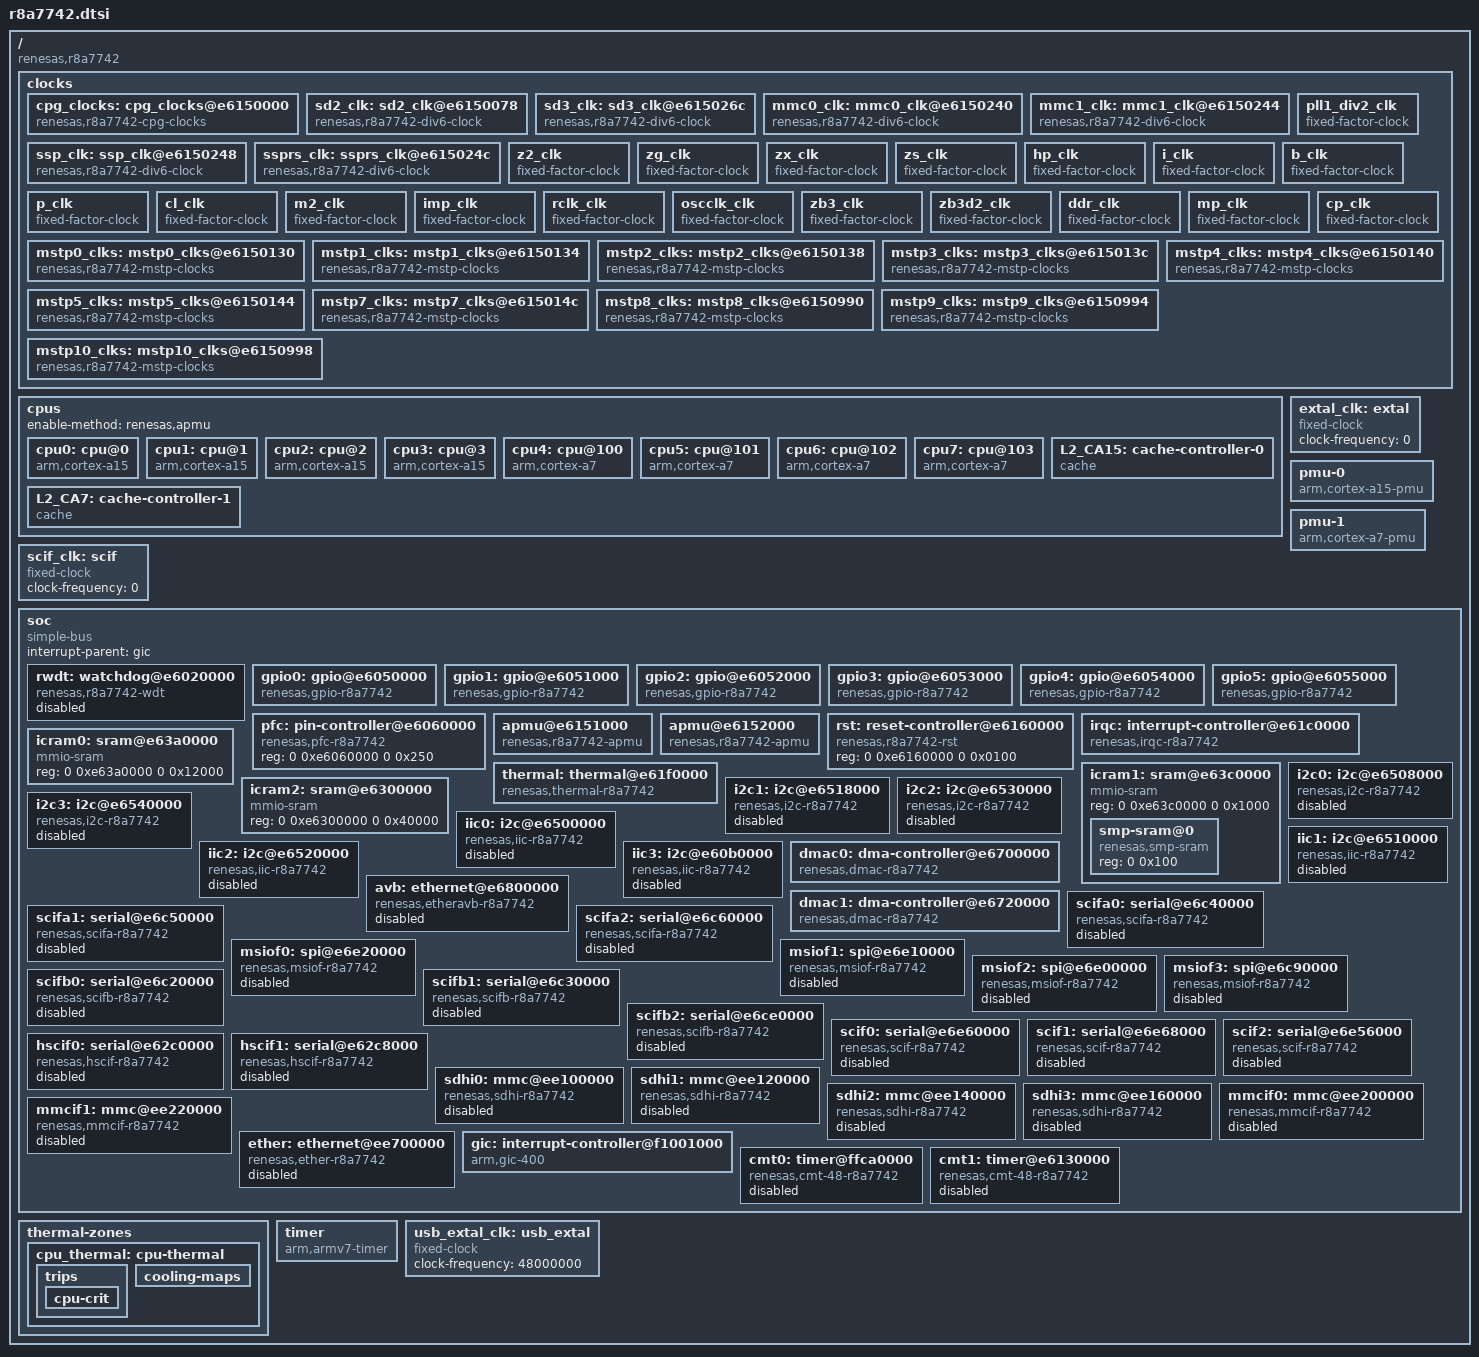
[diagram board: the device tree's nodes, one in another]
// SPDX-License-Identifier: GPL-2.0
/*
 * Device Tree Source for the r8a7742 SoC
 *
 * Copyright (C) 2020 Renesas Electronics Corp.
 */

#include <dt-bindings/interrupt-controller/arm-gic.h>
#include <dt-bindings/interrupt-controller/irq.h>
#include <dt-bindings/clock/r8a7742-clock.h>

/ {
	compatible = "renesas,r8a7742";
	#address-cells = <2>;
	#size-cells = <2>;

	clocks {
		#address-cells = <2>;
		#size-cells = <2>;
		ranges;

		/* Special CPG clocks */
		cpg_clocks: cpg_clocks@e6150000 {
			compatible = "renesas,r8a7742-cpg-clocks",
				     "renesas,rcar-gen2-cpg-clocks";
			reg = <0 0xe6150000 0 0x1000>;
			clocks = <&extal_clk &usb_extal_clk>;
			#clock-cells = <1>;
			clock-output-names = "main", "pll0", "pll1", "pll3",
					     "lb", "qspi", "sdh", "sd0", "sd1",
					     "z", "rcan";
			#power-domain-cells = <0>;
		};

		/* Variable factor clocks */
		sd2_clk: sd2_clk@e6150078 {
			compatible = "renesas,r8a7742-div6-clock", "renesas,cpg-div6-clock";
			reg = <0 0xe6150078 0 4>;
			clocks = <&pll1_div2_clk>;
			#clock-cells = <0>;
			clock-output-names = "sd2";
		};
		sd3_clk: sd3_clk@e615026c {
			compatible = "renesas,r8a7742-div6-clock", "renesas,cpg-div6-clock";
			reg = <0 0xe615026c 0 4>;
			clocks = <&pll1_div2_clk>;
			#clock-cells = <0>;
			clock-output-names = "sd3";
		};
		mmc0_clk: mmc0_clk@e6150240 {
			compatible = "renesas,r8a7742-div6-clock", "renesas,cpg-div6-clock";
			reg = <0 0xe6150240 0 4>;
			clocks = <&pll1_div2_clk>;
			#clock-cells = <0>;
			clock-output-names = "mmc0";
		};
		mmc1_clk: mmc1_clk@e6150244 {
			compatible = "renesas,r8a7742-div6-clock", "renesas,cpg-div6-clock";
			reg = <0 0xe6150244 0 4>;
			clocks = <&pll1_div2_clk>;
			#clock-cells = <0>;
			clock-output-names = "mmc1";
		};
		ssp_clk: ssp_clk@e6150248 {
			compatible = "renesas,r8a7742-div6-clock", "renesas,cpg-div6-clock";
			reg = <0 0xe6150248 0 4>;
			clocks = <&pll1_div2_clk>;
			#clock-cells = <0>;
			clock-output-names = "ssp";
		};
		ssprs_clk: ssprs_clk@e615024c {
			compatible = "renesas,r8a7742-div6-clock", "renesas,cpg-div6-clock";
			reg = <0 0xe615024c 0 4>;
			clocks = <&pll1_div2_clk>;
			#clock-cells = <0>;
			clock-output-names = "ssprs";
		};

		/* Fixed factor clocks */
		pll1_div2_clk: pll1_div2_clk {
			compatible = "fixed-factor-clock";
			clocks = <&cpg_clocks R8A7742_CLK_PLL1>;
			#clock-cells = <0>;
			clock-div = <2>;
			clock-mult = <1>;
			clock-output-names = "pll1_div2";
		};
		z2_clk: z2_clk {
			compatible = "fixed-factor-clock";
			clocks = <&cpg_clocks R8A7742_CLK_PLL1>;
			#clock-cells = <0>;
			clock-div = <2>;
			clock-mult = <1>;
			clock-output-names = "z2";
		};
		zg_clk: zg_clk {
			compatible = "fixed-factor-clock";
			clocks = <&cpg_clocks R8A7742_CLK_PLL1>;
			#clock-cells = <0>;
			clock-div = <3>;
			clock-mult = <1>;
			clock-output-names = "zg";
		};
		zx_clk: zx_clk {
			compatible = "fixed-factor-clock";
			clocks = <&cpg_clocks R8A7742_CLK_PLL1>;
			#clock-cells = <0>;
			clock-div = <3>;
			clock-mult = <1>;
			clock-output-names = "zx";
		};
		zs_clk: zs_clk {
			compatible = "fixed-factor-clock";
			clocks = <&cpg_clocks R8A7742_CLK_PLL1>;
			#clock-cells = <0>;
			clock-div = <6>;
			clock-mult = <1>;
			clock-output-names = "zs";
		};
		hp_clk: hp_clk {
			compatible = "fixed-factor-clock";
			clocks = <&cpg_clocks R8A7742_CLK_PLL1>;
			#clock-cells = <0>;
			clock-div = <12>;
			clock-mult = <1>;
			clock-output-names = "hp";
		};
		i_clk: i_clk {
			compatible = "fixed-factor-clock";
			clocks = <&cpg_clocks R8A7742_CLK_PLL1>;
			#clock-cells = <0>;
			clock-div = <2>;
			clock-mult = <1>;
			clock-output-names = "i";
		};
		b_clk: b_clk {
			compatible = "fixed-factor-clock";
			clocks = <&cpg_clocks R8A7742_CLK_PLL1>;
			#clock-cells = <0>;
			clock-div = <12>;
			clock-mult = <1>;
			clock-output-names = "b";
		};
		p_clk: p_clk {
			compatible = "fixed-factor-clock";
			clocks = <&cpg_clocks R8A7742_CLK_PLL1>;
			#clock-cells = <0>;
			clock-div = <24>;
			clock-mult = <1>;
			clock-output-names = "p";
		};
		cl_clk: cl_clk {
			compatible = "fixed-factor-clock";
			clocks = <&cpg_clocks R8A7742_CLK_PLL1>;
			#clock-cells = <0>;
			clock-div = <48>;
			clock-mult = <1>;
			clock-output-names = "cl";
		};
		m2_clk: m2_clk {
			compatible = "fixed-factor-clock";
			clocks = <&cpg_clocks R8A7742_CLK_PLL1>;
			#clock-cells = <0>;
			clock-div = <8>;
			clock-mult = <1>;
			clock-output-names = "m2";
		};
		imp_clk: imp_clk {
			compatible = "fixed-factor-clock";
			clocks = <&cpg_clocks R8A7742_CLK_PLL1>;
			#clock-cells = <0>;
			clock-div = <4>;
			clock-mult = <1>;
			clock-output-names = "imp";
		};
		rclk_clk: rclk_clk {
			compatible = "fixed-factor-clock";
			clocks = <&cpg_clocks R8A7742_CLK_PLL1>;
			#clock-cells = <0>;
			clock-div = <(48 * 1024)>;
			clock-mult = <1>;
			clock-output-names = "rclk";
		};
		oscclk_clk: oscclk_clk {
			compatible = "fixed-factor-clock";
			clocks = <&cpg_clocks R8A7742_CLK_PLL1>;
			#clock-cells = <0>;
			clock-div = <(12 * 1024)>;
			clock-mult = <1>;
			clock-output-names = "oscclk";
		};
		zb3_clk: zb3_clk {
			compatible = "fixed-factor-clock";
			clocks = <&cpg_clocks R8A7742_CLK_PLL3>;
			#clock-cells = <0>;
			clock-div = <4>;
			clock-mult = <1>;
			clock-output-names = "zb3";
		};
		zb3d2_clk: zb3d2_clk {
			compatible = "fixed-factor-clock";
			clocks = <&cpg_clocks R8A7742_CLK_PLL3>;
			#clock-cells = <0>;
			clock-div = <8>;
			clock-mult = <1>;
			clock-output-names = "zb3d2";
		};
		ddr_clk: ddr_clk {
			compatible = "fixed-factor-clock";
			clocks = <&cpg_clocks R8A7742_CLK_PLL3>;
			#clock-cells = <0>;
			clock-div = <8>;
			clock-mult = <1>;
			clock-output-names = "ddr";
		};
		mp_clk: mp_clk {
			compatible = "fixed-factor-clock";
			clocks = <&pll1_div2_clk>;
			#clock-cells = <0>;
			clock-div = <15>;
			clock-mult = <1>;
			clock-output-names = "mp";
		};
		cp_clk: cp_clk {
			compatible = "fixed-factor-clock";
			clocks = <&extal_clk>;
			#clock-cells = <0>;
			clock-div = <2>;
			clock-mult = <1>;
			clock-output-names = "cp";
		};

		/* Gate clocks */
		mstp0_clks: mstp0_clks@e6150130 {
			compatible = "renesas,r8a7742-mstp-clocks", "renesas,cpg-mstp-clocks";
			reg = <0 0xe6150130 0 4>, <0 0xe6150030 0 4>;
			clocks = <&mp_clk>;
			#clock-cells = <1>;
			clock-indices = <R8A7742_CLK_MSIOF0>;
			clock-output-names = "msiof0";
		};
		mstp1_clks: mstp1_clks@e6150134 {
			compatible = "renesas,r8a7742-mstp-clocks", "renesas,cpg-mstp-clocks";
			reg = <0 0xe6150134 0 4>, <0 0xe6150038 0 4>;
			clocks = <&zs_clk>, <&zs_clk>, <&zs_clk>, <&zs_clk>,
				 <&p_clk>, <&zg_clk>, <&zs_clk>, <&zs_clk>,
				 <&zs_clk>, <&zs_clk>, <&p_clk>, <&p_clk>,
				 <&rclk_clk>, <&cp_clk>, <&zs_clk>, <&zs_clk>,
				 <&zs_clk>, <&zs_clk>;
			#clock-cells = <1>;
			clock-indices = <
				R8A7742_CLK_VCP1 R8A7742_CLK_VCP0
				R8A7742_CLK_VPC1 R8A7742_CLK_VPC0
				R8A7742_CLK_TMU1 R8A7742_CLK_3DG
				R8A7742_CLK_2DDMAC R8A7742_CLK_FDP1_2
				R8A7742_CLK_FDP1_1 R8A7742_CLK_FDP1_0
				R8A7742_CLK_TMU3 R8A7742_CLK_TMU2
				R8A7742_CLK_CMT0 R8A7742_CLK_TMU0
				R8A7742_CLK_VSP1_DU1 R8A7742_CLK_VSP1_DU0
				R8A7742_CLK_VSP1_R R8A7742_CLK_VSP1_S
			>;
			clock-output-names =
				"vcp1", "vcp0", "vpc1", "vpc0", "tmu1",
				"3dg", "2ddmac", "fdp1-2", "fdp1-1", "fdp1-0",
				"tmu3", "tmu2", "cmt0", "tmu0", "vsp1-du1",
				"vsp1-du0", "vspr", "vsps";
		};
		mstp2_clks: mstp2_clks@e6150138 {
			compatible = "renesas,r8a7742-mstp-clocks", "renesas,cpg-mstp-clocks";
			reg = <0 0xe6150138 0 4>, <0 0xe6150040 0 4>;
			clocks = <&mp_clk>, <&mp_clk>, <&mp_clk>, <&mp_clk>, <&mp_clk>,
				 <&mp_clk>, <&mp_clk>, <&mp_clk>, <&mp_clk>, <&zs_clk>,
				 <&zs_clk>;
			#clock-cells = <1>;
			clock-indices = <
				R8A7742_CLK_SCIFA2 R8A7742_CLK_SCIFA1 R8A7742_CLK_SCIFA0
				R8A7742_CLK_MSIOF2 R8A7742_CLK_SCIFB0 R8A7742_CLK_SCIFB1
				R8A7742_CLK_MSIOF1 R8A7742_CLK_MSIOF3 R8A7742_CLK_SCIFB2
				R8A7742_CLK_SYS_DMAC1 R8A7742_CLK_SYS_DMAC0
			>;
			clock-output-names =
				"scifa2", "scifa1", "scifa0", "msiof2", "scifb0",
				"scifb1", "msiof1", "msiof3", "scifb2",
				"sys-dmac1", "sys-dmac0";
		};
		mstp3_clks: mstp3_clks@e615013c {
			compatible = "renesas,r8a7742-mstp-clocks", "renesas,cpg-mstp-clocks";
			reg = <0 0xe615013c 0 4>, <0 0xe6150048 0 4>;
			clocks = <&hp_clk>, <&cp_clk>, <&mmc1_clk>, <&p_clk>, <&sd3_clk>,
				 <&sd2_clk>, <&cpg_clocks R8A7742_CLK_SD1>, <&cpg_clocks R8A7742_CLK_SD0>, <&mmc0_clk>,
				 <&hp_clk>, <&mp_clk>, <&hp_clk>, <&mp_clk>, <&rclk_clk>,
				 <&hp_clk>, <&hp_clk>;
			#clock-cells = <1>;
			clock-indices = <
				R8A7742_CLK_IIC2 R8A7742_CLK_TPU0 R8A7742_CLK_MMCIF1 R8A7742_CLK_SCIF2 R8A7742_CLK_SDHI3
				R8A7742_CLK_SDHI2 R8A7742_CLK_SDHI1 R8A7742_CLK_SDHI0 R8A7742_CLK_MMCIF0
				R8A7742_CLK_IIC0 R8A7742_CLK_PCIEC R8A7742_CLK_IIC1 R8A7742_CLK_SSUSB R8A7742_CLK_CMT1
				R8A7742_CLK_USBDMAC0 R8A7742_CLK_USBDMAC1
			>;
			clock-output-names =
				"iic2", "tpu0", "mmcif1", "scif2", "sdhi3",
				"sdhi2", "sdhi1", "sdhi0", "mmcif0",
				"iic0", "pciec", "iic1", "ssusb", "cmt1",
				"usbdmac0", "usbdmac1";
		};
		mstp4_clks: mstp4_clks@e6150140 {
			compatible = "renesas,r8a7742-mstp-clocks", "renesas,cpg-mstp-clocks";
			reg = <0 0xe6150140 0 4>, <0 0xe615004c 0 4>;
			clocks = <&cp_clk>, <&rclk_clk>, <&zs_clk>;
			#clock-cells = <1>;
			clock-indices = <R8A7742_CLK_IRQC R8A7742_CLK_RWDT R8A7742_CLK_INTC_SYS>;
			clock-output-names = "irqc", "rwdt", "intc-sys";
		};
		mstp5_clks: mstp5_clks@e6150144 {
			compatible = "renesas,r8a7742-mstp-clocks", "renesas,cpg-mstp-clocks";
			reg = <0 0xe6150144 0 4>, <0 0xe615003c 0 4>;
			clocks = <&hp_clk>, <&hp_clk>,
				 <&extal_clk>, <&p_clk>;
			#clock-cells = <1>;
			clock-indices = <
				R8A7742_CLK_AUDIO_DMAC0 R8A7742_CLK_AUDIO_DMAC1
				R8A7742_CLK_THERMAL R8A7742_CLK_PWM
			>;
			clock-output-names = "audmac0", "audmac1",
					     "thermal", "pwm";
		};
		mstp7_clks: mstp7_clks@e615014c {
			compatible = "renesas,r8a7742-mstp-clocks", "renesas,cpg-mstp-clocks";
			reg = <0 0xe615014c 0 4>, <0 0xe61501c4 0 4>;
			clocks = <&mp_clk>, <&hp_clk>, <&zs_clk>, <&zs_clk>, <&p_clk>,
				 <&p_clk>, <&zx_clk>, <&zx_clk>, <&zx_clk>, <&zx_clk>,
				 <&zx_clk>;
			#clock-cells = <1>;
			clock-indices = <
				R8A7742_CLK_EHCI R8A7742_CLK_HSUSB R8A7742_CLK_HSCIF1
				R8A7742_CLK_HSCIF0 R8A7742_CLK_SCIF1 R8A7742_CLK_SCIF0
				R8A7742_CLK_DU2 R8A7742_CLK_DU1 R8A7742_CLK_DU0
				R8A7742_CLK_LVDS1 R8A7742_CLK_LVDS0
			>;
			clock-output-names =
				"ehci", "hsusb", "hscif1", "hscif0", "scif1",
				"scif0", "du2", "du1", "du0", "lvds1", "lvds0";
		};
		mstp8_clks: mstp8_clks@e6150990 {
			compatible = "renesas,r8a7742-mstp-clocks", "renesas,cpg-mstp-clocks";
			reg = <0 0xe6150990 0 4>, <0 0xe61509a0 0 4>;
			clocks = <&zx_clk>, <&zg_clk>, <&zg_clk>, <&zg_clk>,
				 <&zg_clk>, <&hp_clk>, <&p_clk>, <&zs_clk>,
				 <&zs_clk>, <&zg_clk>, <&hp_clk>, <&p_clk>, <&zs_clk>;
			#clock-cells = <1>;
			clock-indices = <
				R8A7742_CLK_R_GP2D R8A7742_CLK_VIN3 R8A7742_CLK_VIN2
				R8A7742_CLK_VIN1 R8A7742_CLK_VIN0
				R8A7742_CLK_ETHERAVB R8A7742_CLK_ETHER
				R8A7742_CLK_SATA1 R8A7742_CLK_SATA0
				R8A7742_CLK_IMR_X2_1 R8A7742_CLK_IMR_X2_0
				R8A7742_CLK_IMR_LSX2_1 R8A7742_CLK_IMR_LSX2_0
			>;
			clock-output-names =
				"r-gp2d", "vin3", "vin2", "vin1", "vin0",
				"etheravb", "ether", "sata1", "sata0",
				"imr-x2-1", "imr-x2-0", "imr-lsx2-1", "imr-lsx2-0";
		};
		mstp9_clks: mstp9_clks@e6150994 {
			compatible = "renesas,r8a7742-mstp-clocks", "renesas,cpg-mstp-clocks";
			reg = <0 0xe6150994 0 4>, <0 0xe61509a4 0 4>;
			clocks = <&cp_clk>, <&cp_clk>, <&cp_clk>,
				 <&cp_clk>, <&cp_clk>, <&cp_clk>,
				 <&p_clk>, <&p_clk>, <&cpg_clocks R8A7742_CLK_QSPI>, <&cp_clk>,
				 <&hp_clk>, <&hp_clk>, <&hp_clk>, <&hp_clk>;
			#clock-cells = <1>;
			clock-indices = <
				R8A7742_CLK_GPIO5 R8A7742_CLK_GPIO4 R8A7742_CLK_GPIO3
				R8A7742_CLK_GPIO2 R8A7742_CLK_GPIO1 R8A7742_CLK_GPIO0
				R8A7742_CLK_RCAN1 R8A7742_CLK_RCAN0 R8A7742_CLK_QSPI_MOD R8A7742_CLK_IICDVFS
				R8A7742_CLK_I2C3 R8A7742_CLK_I2C2 R8A7742_CLK_I2C1 R8A7742_CLK_I2C0
			>;
			clock-output-names =
				"gpio5", "gpio4", "gpio3", "gpio2", "gpio1", "gpio0",
				"rcan1", "rcan0", "qspi_mod", "iic3",
				"i2c3", "i2c2", "i2c1", "i2c0";
		};
		mstp10_clks: mstp10_clks@e6150998 {
			compatible = "renesas,r8a7742-mstp-clocks", "renesas,cpg-mstp-clocks";
			reg = <0 0xe6150998 0 4>, <0 0xe61509a8 0 4>;
			clocks = <&p_clk>,
				<&mstp10_clks R8A7742_CLK_SSI_ALL>, <&mstp10_clks R8A7742_CLK_SSI_ALL>,
				<&mstp10_clks R8A7742_CLK_SSI_ALL>, <&mstp10_clks R8A7742_CLK_SSI_ALL>,
				<&mstp10_clks R8A7742_CLK_SSI_ALL>, <&mstp10_clks R8A7742_CLK_SSI_ALL>,
				<&mstp10_clks R8A7742_CLK_SSI_ALL>, <&mstp10_clks R8A7742_CLK_SSI_ALL>,
				<&mstp10_clks R8A7742_CLK_SSI_ALL>, <&mstp10_clks R8A7742_CLK_SSI_ALL>,
				<&p_clk>,
				<&mstp10_clks R8A7742_CLK_SCU_ALL>, <&mstp10_clks R8A7742_CLK_SCU_ALL>,
				<&mstp10_clks R8A7742_CLK_SCU_ALL>, <&mstp10_clks R8A7742_CLK_SCU_ALL>,
				<&mstp10_clks R8A7742_CLK_SCU_ALL>, <&mstp10_clks R8A7742_CLK_SCU_ALL>,
				<&mstp10_clks R8A7742_CLK_SCU_ALL>, <&mstp10_clks R8A7742_CLK_SCU_ALL>,
				<&mstp10_clks R8A7742_CLK_SCU_ALL>, <&mstp10_clks R8A7742_CLK_SCU_ALL>,
				<&mstp10_clks R8A7742_CLK_SCU_ALL>, <&mstp10_clks R8A7742_CLK_SCU_ALL>,
				<&mstp10_clks R8A7742_CLK_SCU_ALL>, <&mstp10_clks R8A7742_CLK_SCU_ALL>;

			#clock-cells = <1>;
			clock-indices = <
				R8A7742_CLK_SSI_ALL
				R8A7742_CLK_SSI9 R8A7742_CLK_SSI8 R8A7742_CLK_SSI7 R8A7742_CLK_SSI6 R8A7742_CLK_SSI5
				R8A7742_CLK_SSI4 R8A7742_CLK_SSI3 R8A7742_CLK_SSI2 R8A7742_CLK_SSI1 R8A7742_CLK_SSI0
				R8A7742_CLK_SCU_ALL
				R8A7742_CLK_SCU_DVC1 R8A7742_CLK_SCU_DVC0
				R8A7742_CLK_SCU_CTU1_MIX1 R8A7742_CLK_SCU_CTU0_MIX0
				R8A7742_CLK_SCU_SRC9 R8A7742_CLK_SCU_SRC8 R8A7742_CLK_SCU_SRC7 R8A7742_CLK_SCU_SRC6 R8A7742_CLK_SCU_SRC5
				R8A7742_CLK_SCU_SRC4 R8A7742_CLK_SCU_SRC3 R8A7742_CLK_SCU_SRC2 R8A7742_CLK_SCU_SRC1 R8A7742_CLK_SCU_SRC0
			>;
			clock-output-names =
				"ssi-all",
				"ssi9", "ssi8", "ssi7", "ssi6", "ssi5",
				"ssi4", "ssi3", "ssi2", "ssi1", "ssi0",
				"scu-all",
				"scu-dvc1", "scu-dvc0",
				"scu-ctu1-mix1", "scu-ctu0-mix0",
				"scu-src9", "scu-src8", "scu-src7", "scu-src6", "scu-src5",
				"scu-src4", "scu-src3", "scu-src2", "scu-src1", "scu-src0";
		};
	};

	cpus {
		#address-cells = <1>;
		#size-cells = <0>;
		enable-method = "renesas,apmu";

		cpu0: cpu@0 {
			device_type = "cpu";
			compatible = "arm,cortex-a15";
			reg = <0>;
			clock-frequency = <1400000000>;
			clocks = <&cpg_clocks R8A7742_CLK_Z>;
			power-domains = <&cpg_clocks>;
			next-level-cache = <&L2_CA15>;
			capacity-dmips-mhz = <1024>;
			voltage-tolerance = <1>; /* 1% */
			clock-latency = <300000>; /* 300 us */

			/* kHz - uV - OPPs unknown yet */
			operating-points = <1400000 1000000>,
					   <1225000 1000000>,
					   <1050000 1000000>,
					   < 875000 1000000>,
					   < 700000 1000000>,
					   < 350000 1000000>;
		};

		cpu1: cpu@1 {
			device_type = "cpu";
			compatible = "arm,cortex-a15";
			reg = <1>;
			clock-frequency = <1400000000>;
			clocks = <&cpg_clocks R8A7742_CLK_Z>;
			power-domains = <&cpg_clocks>;
			next-level-cache = <&L2_CA15>;
			capacity-dmips-mhz = <1024>;
			voltage-tolerance = <1>; /* 1% */
			clock-latency = <300000>; /* 300 us */

			/* kHz - uV - OPPs unknown yet */
			operating-points = <1400000 1000000>,
					   <1225000 1000000>,
					   <1050000 1000000>,
					   < 875000 1000000>,
					   < 700000 1000000>,
					   < 350000 1000000>;
		};

		cpu2: cpu@2 {
			device_type = "cpu";
			compatible = "arm,cortex-a15";
			reg = <2>;
			clock-frequency = <1400000000>;
			clocks = <&cpg_clocks R8A7742_CLK_Z>;
			power-domains = <&cpg_clocks>;
			next-level-cache = <&L2_CA15>;
			capacity-dmips-mhz = <1024>;
			voltage-tolerance = <1>; /* 1% */
			clock-latency = <300000>; /* 300 us */

			/* kHz - uV - OPPs unknown yet */
			operating-points = <1400000 1000000>,
					   <1225000 1000000>,
					   <1050000 1000000>,
					   < 875000 1000000>,
					   < 700000 1000000>,
					   < 350000 1000000>;
		};

		cpu3: cpu@3 {
			device_type = "cpu";
			compatible = "arm,cortex-a15";
			reg = <3>;
			clock-frequency = <1400000000>;
			clocks = <&cpg_clocks R8A7742_CLK_Z>;
			power-domains = <&cpg_clocks>;
			next-level-cache = <&L2_CA15>;
			capacity-dmips-mhz = <1024>;
			voltage-tolerance = <1>; /* 1% */
			clock-latency = <300000>; /* 300 us */

			/* kHz - uV - OPPs unknown yet */
			operating-points = <1400000 1000000>,
					   <1225000 1000000>,
					   <1050000 1000000>,
					   < 875000 1000000>,
					   < 700000 1000000>,
					   < 350000 1000000>;
		};

		cpu4: cpu@100 {
			device_type = "cpu";
			compatible = "arm,cortex-a7";
			reg = <0x100>;
			clock-frequency = <780000000>;
			clocks = <&cpg_clocks R8A7742_CLK_Z2>;
			power-domains = <&cpg_clocks>;
			next-level-cache = <&L2_CA7>;
		};

		cpu5: cpu@101 {
			device_type = "cpu";
			compatible = "arm,cortex-a7";
			reg = <0x101>;
			clock-frequency = <780000000>;
			clocks = <&cpg_clocks R8A7742_CLK_Z2>;
			power-domains = <&cpg_clocks>;
			next-level-cache = <&L2_CA7>;
		};

		cpu6: cpu@102 {
			device_type = "cpu";
			compatible = "arm,cortex-a7";
			reg = <0x102>;
			clock-frequency = <780000000>;
			clocks = <&cpg_clocks R8A7742_CLK_Z2>;
			power-domains = <&cpg_clocks>;
			next-level-cache = <&L2_CA7>;
		};

		cpu7: cpu@103 {
			device_type = "cpu";
			compatible = "arm,cortex-a7";
			reg = <0x103>;
			clock-frequency = <780000000>;
			clocks = <&cpg_clocks R8A7742_CLK_Z2>;
			power-domains = <&cpg_clocks>;
			next-level-cache = <&L2_CA7>;
		};

		L2_CA15: cache-controller-0 {
			compatible = "cache";
			power-domains = <&cpg_clocks>;
			cache-unified;
			cache-level = <2>;
		};

		L2_CA7: cache-controller-1 {
			compatible = "cache";
			power-domains = <&cpg_clocks>;
			cache-unified;
			cache-level = <2>;
		};
	};

	/* External root clock */
	extal_clk: extal {
		compatible = "fixed-clock";
		#clock-cells = <0>;
		/* This value must be overridden by the board. */
		clock-frequency = <0>;
	};

	pmu-0 {
		compatible = "arm,cortex-a15-pmu";
		interrupts-extended = <&gic GIC_SPI 72 IRQ_TYPE_LEVEL_HIGH>,
				      <&gic GIC_SPI 73 IRQ_TYPE_LEVEL_HIGH>,
				      <&gic GIC_SPI 74 IRQ_TYPE_LEVEL_HIGH>,
				      <&gic GIC_SPI 75 IRQ_TYPE_LEVEL_HIGH>;
		interrupt-affinity = <&cpu0>, <&cpu1>, <&cpu2>, <&cpu3>;
	};

	pmu-1 {
		compatible = "arm,cortex-a7-pmu";
		interrupts-extended = <&gic GIC_SPI 82 IRQ_TYPE_LEVEL_HIGH>,
				      <&gic GIC_SPI 83 IRQ_TYPE_LEVEL_HIGH>,
				      <&gic GIC_SPI 84 IRQ_TYPE_LEVEL_HIGH>,
				      <&gic GIC_SPI 85 IRQ_TYPE_LEVEL_HIGH>;
		interrupt-affinity = <&cpu4>, <&cpu5>, <&cpu6>, <&cpu7>;
	};

	/* External SCIF clock */
	scif_clk: scif {
		compatible = "fixed-clock";
		#clock-cells = <0>;
		/* This value must be overridden by the board. */
		clock-frequency = <0>;
	};

	soc {
		compatible = "simple-bus";
		interrupt-parent = <&gic>;

		#address-cells = <2>;
		#size-cells = <2>;
		ranges;

		rwdt: watchdog@e6020000 {
			compatible = "renesas,r8a7742-wdt",
				     "renesas,rcar-gen2-wdt";
			reg = <0 0xe6020000 0 0x0c>;
			interrupts = <GIC_SPI 140 IRQ_TYPE_LEVEL_HIGH>;
			clocks = <&mstp4_clks R8A7742_CLK_RWDT>;
			power-domains = <&cpg_clocks>;
			status = "disabled";
		};

		gpio0: gpio@e6050000 {
			compatible = "renesas,gpio-r8a7742",
				     "renesas,rcar-gen2-gpio";
			reg = <0 0xe6050000 0 0x50>;
			interrupts = <GIC_SPI 4 IRQ_TYPE_LEVEL_HIGH>;
			#gpio-cells = <2>;
			gpio-controller;
			gpio-ranges = <&pfc 0 0 32>;
			#interrupt-cells = <2>;
			interrupt-controller;
			clocks = <&mstp9_clks R8A7742_CLK_GPIO0>;
			power-domains = <&cpg_clocks>;
		};

		gpio1: gpio@e6051000 {
			compatible = "renesas,gpio-r8a7742",
				     "renesas,rcar-gen2-gpio";
			reg = <0 0xe6051000 0 0x50>;
			interrupts = <GIC_SPI 5 IRQ_TYPE_LEVEL_HIGH>;
			#gpio-cells = <2>;
			gpio-controller;
			gpio-ranges = <&pfc 0 32 30>;
			#interrupt-cells = <2>;
			interrupt-controller;
			clocks = <&mstp9_clks R8A7742_CLK_GPIO1>;
			power-domains = <&cpg_clocks>;
		};

		gpio2: gpio@e6052000 {
			compatible = "renesas,gpio-r8a7742",
				     "renesas,rcar-gen2-gpio";
			reg = <0 0xe6052000 0 0x50>;
			interrupts = <GIC_SPI 6 IRQ_TYPE_LEVEL_HIGH>;
			#gpio-cells = <2>;
			gpio-controller;
			gpio-ranges = <&pfc 0 64 30>;
			#interrupt-cells = <2>;
			interrupt-controller;
			clocks = <&mstp9_clks R8A7742_CLK_GPIO2>;
			power-domains = <&cpg_clocks>;
		};

		gpio3: gpio@e6053000 {
			compatible = "renesas,gpio-r8a7742",
				     "renesas,rcar-gen2-gpio";
			reg = <0 0xe6053000 0 0x50>;
			interrupts = <GIC_SPI 7 IRQ_TYPE_LEVEL_HIGH>;
			#gpio-cells = <2>;
			gpio-controller;
			gpio-ranges = <&pfc 0 96 32>;
			#interrupt-cells = <2>;
			interrupt-controller;
			clocks = <&mstp9_clks R8A7742_CLK_GPIO3>;
			power-domains = <&cpg_clocks>;
		};

		gpio4: gpio@e6054000 {
			compatible = "renesas,gpio-r8a7742",
				     "renesas,rcar-gen2-gpio";
			reg = <0 0xe6054000 0 0x50>;
			interrupts = <GIC_SPI 8 IRQ_TYPE_LEVEL_HIGH>;
			#gpio-cells = <2>;
			gpio-controller;
			gpio-ranges = <&pfc 0 128 32>;
			#interrupt-cells = <2>;
			interrupt-controller;
			clocks = <&mstp9_clks R8A7742_CLK_GPIO4>;
			power-domains = <&cpg_clocks>;
		};

		gpio5: gpio@e6055000 {
			compatible = "renesas,gpio-r8a7742",
				     "renesas,rcar-gen2-gpio";
			reg = <0 0xe6055000 0 0x50>;
			interrupts = <GIC_SPI 9 IRQ_TYPE_LEVEL_HIGH>;
			#gpio-cells = <2>;
			gpio-controller;
			gpio-ranges = <&pfc 0 160 32>;
			#interrupt-cells = <2>;
			interrupt-controller;
			clocks = <&mstp9_clks R8A7742_CLK_GPIO5>;
			power-domains = <&cpg_clocks>;
		};

		pfc: pin-controller@e6060000 {
			compatible = "renesas,pfc-r8a7742";
			reg = <0 0xe6060000 0 0x250>;
		};

		apmu@e6151000 {
			compatible = "renesas,r8a7742-apmu", "renesas,apmu";
			reg = <0 0xe6151000 0 0x188>;
			cpus = <&cpu4 &cpu5 &cpu6 &cpu7>;
		};

		apmu@e6152000 {
			compatible = "renesas,r8a7742-apmu", "renesas,apmu";
			reg = <0 0xe6152000 0 0x188>;
			cpus = <&cpu0 &cpu1 &cpu2 &cpu3>;
		};

		rst: reset-controller@e6160000 {
			compatible = "renesas,r8a7742-rst";
			reg = <0 0xe6160000 0 0x0100>;
		};

		irqc: interrupt-controller@e61c0000 {
			compatible = "renesas,irqc-r8a7742", "renesas,irqc";
			#interrupt-cells = <2>;
			interrupt-controller;
			reg = <0 0xe61c0000 0 0x200>;
			interrupts = <GIC_SPI 0 IRQ_TYPE_LEVEL_HIGH>,
				     <GIC_SPI 1 IRQ_TYPE_LEVEL_HIGH>,
				     <GIC_SPI 2 IRQ_TYPE_LEVEL_HIGH>,
				     <GIC_SPI 3 IRQ_TYPE_LEVEL_HIGH>;
			clocks = <&mstp4_clks R8A7742_CLK_IRQC>;
			power-domains = <&cpg_clocks>;
		};

		thermal: thermal@e61f0000 {
			compatible = "renesas,thermal-r8a7742",
				     "renesas,rcar-gen2-thermal";
			reg = <0 0xe61f0000 0 0x10>, <0 0xe61f0100 0 0x38>;
			interrupts = <GIC_SPI 69 IRQ_TYPE_LEVEL_HIGH>;
			clocks = <&mstp5_clks R8A7742_CLK_THERMAL>;
			power-domains = <&cpg_clocks>;
			#thermal-sensor-cells = <0>;
		};

		icram0: sram@e63a0000 {
			compatible = "mmio-sram";
			reg = <0 0xe63a0000 0 0x12000>;
			#address-cells = <1>;
			#size-cells = <1>;
			ranges = <0 0 0xe63a0000 0x12000>;
		};

		icram1: sram@e63c0000 {
			compatible = "mmio-sram";
			reg = <0 0xe63c0000 0 0x1000>;
			#address-cells = <1>;
			#size-cells = <1>;
			ranges = <0 0 0xe63c0000 0x1000>;

			smp-sram@0 {
				compatible = "renesas,smp-sram";
				reg = <0 0x100>;
			};
		};

		icram2: sram@e6300000 {
			compatible = "mmio-sram";
			reg = <0 0xe6300000 0 0x40000>;
			#address-cells = <1>;
			#size-cells = <1>;
			ranges = <0 0 0xe6300000 0x40000>;
		};

		i2c0: i2c@e6508000 {
			#address-cells = <1>;
			#size-cells = <0>;
			compatible = "renesas,i2c-r8a7742",
				     "renesas,rcar-gen2-i2c";
			reg = <0 0xe6508000 0 0x40>;
			interrupts = <GIC_SPI 287 IRQ_TYPE_LEVEL_HIGH>;
			clocks = <&mstp9_clks R8A7742_CLK_I2C0>;
			power-domains = <&cpg_clocks>;
			status = "disabled";
		};

		i2c1: i2c@e6518000 {
			#address-cells = <1>;
			#size-cells = <0>;
			compatible = "renesas,i2c-r8a7742",
				     "renesas,rcar-gen2-i2c";
			reg = <0 0xe6518000 0 0x40>;
			interrupts = <GIC_SPI 288 IRQ_TYPE_LEVEL_HIGH>;
			clocks = <&mstp9_clks R8A7742_CLK_I2C1>;
			power-domains = <&cpg_clocks>;
			status = "disabled";
		};

		i2c2: i2c@e6530000 {
			#address-cells = <1>;
			#size-cells = <0>;
			compatible = "renesas,i2c-r8a7742",
				     "renesas,rcar-gen2-i2c";
			reg = <0 0xe6530000 0 0x40>;
			interrupts = <GIC_SPI 286 IRQ_TYPE_LEVEL_HIGH>;
			clocks = <&mstp9_clks R8A7742_CLK_I2C2>;
			power-domains = <&cpg_clocks>;
			status = "disabled";
		};

		i2c3: i2c@e6540000 {
			#address-cells = <1>;
			#size-cells = <0>;
			compatible = "renesas,i2c-r8a7742",
				     "renesas,rcar-gen2-i2c";
			reg = <0 0xe6540000 0 0x40>;
			interrupts = <GIC_SPI 290 IRQ_TYPE_LEVEL_HIGH>;
			clocks = <&mstp9_clks R8A7742_CLK_I2C3>;
			power-domains = <&cpg_clocks>;
			status = "disabled";
		};

		iic0: i2c@e6500000 {
			#address-cells = <1>;
			#size-cells = <0>;
			compatible = "renesas,iic-r8a7742",
				     "renesas,rcar-gen2-iic",
				     "renesas,rmobile-iic";
			reg = <0 0xe6500000 0 0x425>;
			interrupts = <GIC_SPI 174 IRQ_TYPE_LEVEL_HIGH>;
			clocks = <&mstp3_clks R8A7742_CLK_IIC0>;
			dmas = <&dmac0 0x61>, <&dmac0 0x62>,
			       <&dmac1 0x61>, <&dmac1 0x62>;
			dma-names = "tx", "rx", "tx", "rx";
			power-domains = <&cpg_clocks>;
			status = "disabled";
		};

		iic1: i2c@e6510000 {
			#address-cells = <1>;
			#size-cells = <0>;
			compatible = "renesas,iic-r8a7742",
				     "renesas,rcar-gen2-iic",
				     "renesas,rmobile-iic";
			reg = <0 0xe6510000 0 0x425>;
			interrupts = <GIC_SPI 175 IRQ_TYPE_LEVEL_HIGH>;
			clocks = <&mstp3_clks R8A7742_CLK_IIC1>;
			dmas = <&dmac0 0x65>, <&dmac0 0x66>,
			       <&dmac1 0x65>, <&dmac1 0x66>;
			dma-names = "tx", "rx", "tx", "rx";
			power-domains = <&cpg_clocks>;
			status = "disabled";
		};

		iic2: i2c@e6520000 {
			#address-cells = <1>;
			#size-cells = <0>;
			compatible = "renesas,iic-r8a7742",
				     "renesas,rcar-gen2-iic",
				     "renesas,rmobile-iic";
			reg = <0 0xe6520000 0 0x425>;
			interrupts = <GIC_SPI 176 IRQ_TYPE_LEVEL_HIGH>;
			clocks = <&mstp3_clks R8A7742_CLK_IIC2>;
			dmas = <&dmac0 0x69>, <&dmac0 0x6a>,
			       <&dmac1 0x69>, <&dmac1 0x6a>;
			dma-names = "tx", "rx", "tx", "rx";
			power-domains = <&cpg_clocks>;
			status = "disabled";
		};

		iic3: i2c@e60b0000 {
			#address-cells = <1>;
			#size-cells = <0>;
			compatible = "renesas,iic-r8a7742";
			reg = <0 0xe60b0000 0 0x425>;
			interrupts = <GIC_SPI 173 IRQ_TYPE_LEVEL_HIGH>;
			clocks = <&mstp9_clks R8A7742_CLK_IICDVFS>;
			dmas = <&dmac0 0x77>, <&dmac0 0x78>,
			       <&dmac1 0x77>, <&dmac1 0x78>;
			dma-names = "tx", "rx", "tx", "rx";
			power-domains = <&cpg_clocks>;
			status = "disabled";
		};

		dmac0: dma-controller@e6700000 {
			compatible = "renesas,dmac-r8a7742",
				     "renesas,rcar-dmac";
			reg = <0 0xe6700000 0 0x20000>;
			interrupts = <GIC_SPI 197 IRQ_TYPE_LEVEL_HIGH>,
				     <GIC_SPI 200 IRQ_TYPE_LEVEL_HIGH>,
				     <GIC_SPI 201 IRQ_TYPE_LEVEL_HIGH>,
				     <GIC_SPI 202 IRQ_TYPE_LEVEL_HIGH>,
				     <GIC_SPI 203 IRQ_TYPE_LEVEL_HIGH>,
				     <GIC_SPI 204 IRQ_TYPE_LEVEL_HIGH>,
				     <GIC_SPI 205 IRQ_TYPE_LEVEL_HIGH>,
				     <GIC_SPI 206 IRQ_TYPE_LEVEL_HIGH>,
				     <GIC_SPI 207 IRQ_TYPE_LEVEL_HIGH>,
				     <GIC_SPI 208 IRQ_TYPE_LEVEL_HIGH>,
				     <GIC_SPI 209 IRQ_TYPE_LEVEL_HIGH>,
				     <GIC_SPI 210 IRQ_TYPE_LEVEL_HIGH>,
				     <GIC_SPI 211 IRQ_TYPE_LEVEL_HIGH>,
				     <GIC_SPI 212 IRQ_TYPE_LEVEL_HIGH>,
				     <GIC_SPI 213 IRQ_TYPE_LEVEL_HIGH>,
				     <GIC_SPI 214 IRQ_TYPE_LEVEL_HIGH>;
			interrupt-names = "error",
					  "ch0", "ch1", "ch2", "ch3",
					  "ch4", "ch5", "ch6", "ch7",
					  "ch8", "ch9", "ch10", "ch11",
					  "ch12", "ch13", "ch14";
			clocks = <&mstp2_clks R8A7742_CLK_SYS_DMAC0>;
			clock-names = "fck";
			power-domains = <&cpg_clocks>;
			#dma-cells = <1>;
			dma-channels = <15>;
		};

		dmac1: dma-controller@e6720000 {
			compatible = "renesas,dmac-r8a7742",
				     "renesas,rcar-dmac";
			reg = <0 0xe6720000 0 0x20000>;
			interrupts = <GIC_SPI 220 IRQ_TYPE_LEVEL_HIGH>,
				     <GIC_SPI 216 IRQ_TYPE_LEVEL_HIGH>,
				     <GIC_SPI 217 IRQ_TYPE_LEVEL_HIGH>,
				     <GIC_SPI 218 IRQ_TYPE_LEVEL_HIGH>,
				     <GIC_SPI 219 IRQ_TYPE_LEVEL_HIGH>,
				     <GIC_SPI 308 IRQ_TYPE_LEVEL_HIGH>,
				     <GIC_SPI 309 IRQ_TYPE_LEVEL_HIGH>,
				     <GIC_SPI 310 IRQ_TYPE_LEVEL_HIGH>,
				     <GIC_SPI 311 IRQ_TYPE_LEVEL_HIGH>,
				     <GIC_SPI 312 IRQ_TYPE_LEVEL_HIGH>,
				     <GIC_SPI 313 IRQ_TYPE_LEVEL_HIGH>,
				     <GIC_SPI 314 IRQ_TYPE_LEVEL_HIGH>,
				     <GIC_SPI 315 IRQ_TYPE_LEVEL_HIGH>,
				     <GIC_SPI 316 IRQ_TYPE_LEVEL_HIGH>,
				     <GIC_SPI 317 IRQ_TYPE_LEVEL_HIGH>,
				     <GIC_SPI 318 IRQ_TYPE_LEVEL_HIGH>;
			interrupt-names = "error",
					  "ch0", "ch1", "ch2", "ch3",
					  "ch4", "ch5", "ch6", "ch7",
					  "ch8", "ch9", "ch10", "ch11",
					  "ch12", "ch13", "ch14";
			clocks = <&mstp2_clks R8A7742_CLK_SYS_DMAC1>;
			clock-names = "fck";
			power-domains = <&cpg_clocks>;
			#dma-cells = <1>;
			dma-channels = <15>;
		};

		avb: ethernet@e6800000 {
			compatible = "renesas,etheravb-r8a7742",
				     "renesas,etheravb-rcar-gen2";
			reg = <0 0xe6800000 0 0x800>, <0 0xee0e8000 0 0x4000>;
			interrupts = <GIC_SPI 163 IRQ_TYPE_LEVEL_HIGH>;
			clocks = <&mstp8_clks R8A7742_CLK_ETHERAVB>;
			power-domains = <&cpg_clocks>;
			#address-cells = <1>;
			#size-cells = <0>;
			status = "disabled";
		};

		scifa0: serial@e6c40000 {
			compatible = "renesas,scifa-r8a7742",
				     "renesas,scifa";
			reg = <0 0xe6c40000 0 0x40>;
			interrupts = <GIC_SPI 144 IRQ_TYPE_LEVEL_HIGH>;
			clocks = <&mstp2_clks R8A7742_CLK_SCIFA0>;
			clock-names = "sci_ick";
			dmas = <&dmac0 0x21>, <&dmac0 0x22>,
			       <&dmac1 0x21>, <&dmac1 0x22>;
			dma-names = "tx", "rx", "tx", "rx";
			power-domains = <&cpg_clocks>;
			status = "disabled";
		};

		scifa1: serial@e6c50000 {
			compatible = "renesas,scifa-r8a7742",
				     "renesas,scifa";
			reg = <0 0xe6c50000 0 0x40>;
			interrupts = <GIC_SPI 145 IRQ_TYPE_LEVEL_HIGH>;
			clocks = <&mstp2_clks R8A7742_CLK_SCIFA1>;
			clock-names = "sci_ick";
			dmas = <&dmac0 0x25>, <&dmac0 0x26>,
			       <&dmac1 0x25>, <&dmac1 0x26>;
			dma-names = "tx", "rx", "tx", "rx";
			power-domains = <&cpg_clocks>;
			status = "disabled";
		};

		scifa2: serial@e6c60000 {
			compatible = "renesas,scifa-r8a7742",
				     "renesas,scifa";
			reg = <0 0xe6c60000 0 0x40>;
			interrupts = <GIC_SPI 151 IRQ_TYPE_LEVEL_HIGH>;
			clocks = <&mstp2_clks R8A7742_CLK_SCIFA2>;
			clock-names = "sci_ick";
			dmas = <&dmac0 0x27>, <&dmac0 0x28>,
			       <&dmac1 0x27>, <&dmac1 0x28>;
			dma-names = "tx", "rx", "tx", "rx";
			power-domains = <&cpg_clocks>;
			status = "disabled";
		};

		msiof0: spi@e6e20000 {
			compatible = "renesas,msiof-r8a7742",
				     "renesas,rcar-gen2-msiof";
			reg = <0 0xe6e20000 0 0x0064>;
			interrupts = <GIC_SPI 156 IRQ_TYPE_LEVEL_HIGH>;
			clocks = <&mstp0_clks R8A7742_CLK_MSIOF0>;
			dmas = <&dmac0 0x51>, <&dmac0 0x52>,
			       <&dmac1 0x51>, <&dmac1 0x52>;
			dma-names = "tx", "rx", "tx", "rx";
			power-domains = <&cpg_clocks>;
			#address-cells = <1>;
			#size-cells = <0>;
			status = "disabled";
		};

		msiof1: spi@e6e10000 {
			compatible = "renesas,msiof-r8a7742",
				     "renesas,rcar-gen2-msiof";
			reg = <0 0xe6e10000 0 0x0064>;
			interrupts = <GIC_SPI 157 IRQ_TYPE_LEVEL_HIGH>;
			clocks = <&mstp2_clks R8A7742_CLK_MSIOF1>;
			dmas = <&dmac0 0x55>, <&dmac0 0x56>,
			       <&dmac1 0x55>, <&dmac1 0x56>;
			dma-names = "tx", "rx", "tx", "rx";
			power-domains = <&cpg_clocks>;
			#address-cells = <1>;
			#size-cells = <0>;
			status = "disabled";
		};

		msiof2: spi@e6e00000 {
			compatible = "renesas,msiof-r8a7742",
				     "renesas,rcar-gen2-msiof";
			reg = <0 0xe6e00000 0 0x0064>;
			interrupts = <GIC_SPI 158 IRQ_TYPE_LEVEL_HIGH>;
			clocks = <&mstp2_clks R8A7742_CLK_MSIOF2>;
			dmas = <&dmac0 0x41>, <&dmac0 0x42>,
			       <&dmac1 0x41>, <&dmac1 0x42>;
			dma-names = "tx", "rx", "tx", "rx";
			power-domains = <&cpg_clocks>;
			#address-cells = <1>;
			#size-cells = <0>;
			status = "disabled";
		};

		msiof3: spi@e6c90000 {
			compatible = "renesas,msiof-r8a7742",
				     "renesas,rcar-gen2-msiof";
			reg = <0 0xe6c90000 0 0x0064>;
			interrupts = <GIC_SPI 159 IRQ_TYPE_LEVEL_HIGH>;
			clocks = <&mstp2_clks R8A7742_CLK_MSIOF3>;
			dmas = <&dmac0 0x45>, <&dmac0 0x46>,
			       <&dmac1 0x45>, <&dmac1 0x46>;
			dma-names = "tx", "rx", "tx", "rx";
			power-domains = <&cpg_clocks>;
			#address-cells = <1>;
			#size-cells = <0>;
			status = "disabled";
		};

		scifb0: serial@e6c20000 {
			compatible = "renesas,scifb-r8a7742",
				     "renesas,scifb";
			reg = <0 0xe6c20000 0 0x100>;
			interrupts = <GIC_SPI 148 IRQ_TYPE_LEVEL_HIGH>;
			clocks = <&mstp2_clks R8A7742_CLK_SCIFB0>;
			clock-names = "sci_ick";
			dmas = <&dmac0 0x3d>, <&dmac0 0x3e>,
			       <&dmac1 0x3d>, <&dmac1 0x3e>;
			dma-names = "tx", "rx", "tx", "rx";
			power-domains = <&cpg_clocks>;
			status = "disabled";
		};

		scifb1: serial@e6c30000 {
			compatible = "renesas,scifb-r8a7742",
				     "renesas,scifb";
			reg = <0 0xe6c30000 0 0x100>;
			interrupts = <GIC_SPI 149 IRQ_TYPE_LEVEL_HIGH>;
			clocks = <&mstp2_clks R8A7742_CLK_SCIFB1>;
			clock-names = "sci_ick";
			dmas = <&dmac0 0x19>, <&dmac0 0x1a>,
			       <&dmac1 0x19>, <&dmac1 0x1a>;
			dma-names = "tx", "rx", "tx", "rx";
			power-domains = <&cpg_clocks>;
			status = "disabled";
		};

		scifb2: serial@e6ce0000 {
			compatible = "renesas,scifb-r8a7742",
				     "renesas,scifb";
			reg = <0 0xe6ce0000 0 0x100>;
			interrupts = <GIC_SPI 150 IRQ_TYPE_LEVEL_HIGH>;
			clocks = <&mstp2_clks R8A7742_CLK_SCIFB2>;
			clock-names = "sci_ick";
			dmas = <&dmac0 0x1d>, <&dmac0 0x1e>,
			       <&dmac1 0x1d>, <&dmac1 0x1e>;
			dma-names = "tx", "rx", "tx", "rx";
			power-domains = <&cpg_clocks>;
			status = "disabled";
		};

		scif0: serial@e6e60000 {
			compatible = "renesas,scif-r8a7742",
				     "renesas,scif";
			reg = <0 0xe6e60000 0 0x40>;
			interrupts = <GIC_SPI 152 IRQ_TYPE_LEVEL_HIGH>;
			clocks = <&mstp7_clks R8A7742_CLK_SCIF0>,
				 <&zs_clk>, <&scif_clk>;
			clock-names = "sci_ick", "brg_int", "scif_clk";
			dmas = <&dmac0 0x29>, <&dmac0 0x2a>,
			       <&dmac1 0x29>, <&dmac1 0x2a>;
			dma-names = "tx", "rx", "tx", "rx";
			power-domains = <&cpg_clocks>;
			status = "disabled";
		};

		scif1: serial@e6e68000 {
			compatible = "renesas,scif-r8a7742",
				     "renesas,scif";
			reg = <0 0xe6e68000 0 0x40>;
			interrupts = <GIC_SPI 153 IRQ_TYPE_LEVEL_HIGH>;
			clocks = <&mstp7_clks R8A7742_CLK_SCIF1>,
				 <&zs_clk>, <&scif_clk>;
			clock-names = "sci_ick", "brg_int", "scif_clk";
			dmas = <&dmac0 0x2d>, <&dmac0 0x2e>,
			       <&dmac1 0x2d>, <&dmac1 0x2e>;
			dma-names = "tx", "rx", "tx", "rx";
			power-domains = <&cpg_clocks>;
			status = "disabled";
		};

		scif2: serial@e6e56000 {
			compatible = "renesas,scif-r8a7742",
				     "renesas,scif";
			reg = <0 0xe6e56000 0 0x40>;
			interrupts = <GIC_SPI 164 IRQ_TYPE_LEVEL_HIGH>;
			clocks = <&mstp7_clks R8A7742_CLK_SCIF2>,
				 <&zs_clk>, <&scif_clk>;
			clock-names = "sci_ick", "brg_int", "scif_clk";
			dmas = <&dmac0 0x2b>, <&dmac0 0x2c>,
			       <&dmac1 0x2b>, <&dmac1 0x2c>;
			dma-names = "tx", "rx", "tx", "rx";
			power-domains = <&cpg_clocks>;
			status = "disabled";
		};

		hscif0: serial@e62c0000 {
			compatible = "renesas,hscif-r8a7742",
				     "renesas,hscif";
			reg = <0 0xe62c0000 0 0x60>;
			interrupts = <GIC_SPI 154 IRQ_TYPE_LEVEL_HIGH>;
			clocks = <&mstp7_clks R8A7742_CLK_HSCIF0>,
				 <&zs_clk>, <&scif_clk>;
			clock-names = "sci_ick", "brg_int", "scif_clk";
			dmas = <&dmac0 0x39>, <&dmac0 0x3a>,
			       <&dmac1 0x39>, <&dmac1 0x3a>;
			dma-names = "tx", "rx", "tx", "rx";
			power-domains = <&cpg_clocks>;
			status = "disabled";
		};

		hscif1: serial@e62c8000 {
			compatible = "renesas,hscif-r8a7742",
				     "renesas,hscif";
			reg = <0 0xe62c8000 0 0x60>;
			interrupts = <GIC_SPI 155 IRQ_TYPE_LEVEL_HIGH>;
			clocks = <&mstp7_clks R8A7742_CLK_HSCIF1>,
				 <&zs_clk>, <&scif_clk>;
			clock-names = "sci_ick", "brg_int", "scif_clk";
			dmas = <&dmac0 0x4d>, <&dmac0 0x4e>,
			       <&dmac1 0x4d>, <&dmac1 0x4e>;
			dma-names = "tx", "rx", "tx", "rx";
			power-domains = <&cpg_clocks>;
			status = "disabled";
		};

		sdhi0: mmc@ee100000 {
			compatible = "renesas,sdhi-r8a7742",
				     "renesas,rcar-gen2-sdhi";
			reg = <0 0xee100000 0 0x328>;
			interrupts = <GIC_SPI 165 IRQ_TYPE_LEVEL_HIGH>;
			clocks = <&mstp3_clks R8A7742_CLK_SDHI0>;
			dmas = <&dmac0 0xcd>, <&dmac0 0xce>,
			       <&dmac1 0xcd>, <&dmac1 0xce>;
			dma-names = "tx", "rx", "tx", "rx";
			max-frequency = <195000000>;
			power-domains = <&cpg_clocks>;
			status = "disabled";
		};

		sdhi1: mmc@ee120000 {
			compatible = "renesas,sdhi-r8a7742",
				     "renesas,rcar-gen2-sdhi";
			reg = <0 0xee120000 0 0x328>;
			interrupts = <GIC_SPI 166 IRQ_TYPE_LEVEL_HIGH>;
			clocks = <&mstp3_clks R8A7742_CLK_SDHI1>;
			dmas = <&dmac0 0xc9>, <&dmac0 0xca>,
			       <&dmac1 0xc9>, <&dmac1 0xca>;
			dma-names = "tx", "rx", "tx", "rx";
			max-frequency = <195000000>;
			power-domains = <&cpg_clocks>;
			status = "disabled";
		};

		sdhi2: mmc@ee140000 {
			compatible = "renesas,sdhi-r8a7742",
				     "renesas,rcar-gen2-sdhi";
			reg = <0 0xee140000 0 0x100>;
			interrupts = <GIC_SPI 167 IRQ_TYPE_LEVEL_HIGH>;
			clocks = <&mstp3_clks R8A7742_CLK_SDHI2>;
			dmas = <&dmac0 0xc1>, <&dmac0 0xc2>,
			       <&dmac1 0xc1>, <&dmac1 0xc2>;
			dma-names = "tx", "rx", "tx", "rx";
			max-frequency = <97500000>;
			power-domains = <&cpg_clocks>;
			status = "disabled";
		};

		sdhi3: mmc@ee160000 {
			compatible = "renesas,sdhi-r8a7742",
				     "renesas,rcar-gen2-sdhi";
			reg = <0 0xee160000 0 0x100>;
			interrupts = <GIC_SPI 168 IRQ_TYPE_LEVEL_HIGH>;
			clocks = <&mstp3_clks R8A7742_CLK_SDHI3>;
			dmas = <&dmac0 0xd3>, <&dmac0 0xd4>,
			       <&dmac1 0xd3>, <&dmac1 0xd4>;
			dma-names = "tx", "rx", "tx", "rx";
			max-frequency = <97500000>;
			power-domains = <&cpg_clocks>;
			status = "disabled";
		};

		mmcif0: mmc@ee200000 {
			compatible = "renesas,mmcif-r8a7742",
				     "renesas,sh-mmcif";
			reg = <0 0xee200000 0 0x80>;
			interrupts = <GIC_SPI 169 IRQ_TYPE_LEVEL_HIGH>;
			clocks = <&mstp3_clks R8A7742_CLK_MMCIF0>;
			dmas = <&dmac0 0xd1>, <&dmac0 0xd2>,
			       <&dmac1 0xd1>, <&dmac1 0xd2>;
			dma-names = "tx", "rx", "tx", "rx";
			power-domains = <&cpg_clocks>;
			reg-io-width = <4>;
			status = "disabled";
			max-frequency = <97500000>;
		};

		mmcif1: mmc@ee220000 {
			compatible = "renesas,mmcif-r8a7742",
				     "renesas,sh-mmcif";
			reg = <0 0xee220000 0 0x80>;
			interrupts = <GIC_SPI 170 IRQ_TYPE_LEVEL_HIGH>;
			clocks = <&mstp3_clks R8A7742_CLK_MMCIF1>;
			dmas = <&dmac0 0xe1>, <&dmac0 0xe2>,
			       <&dmac1 0xe1>, <&dmac1 0xe2>;
			dma-names = "tx", "rx", "tx", "rx";
			power-domains = <&cpg_clocks>;
			reg-io-width = <4>;
			status = "disabled";
			max-frequency = <97500000>;
		};

		ether: ethernet@ee700000 {
			compatible = "renesas,ether-r8a7742";
			reg = <0 0xee700000 0 0x400>;
			interrupts = <GIC_SPI 162 IRQ_TYPE_LEVEL_HIGH>;
			clocks = <&mstp8_clks R8A7742_CLK_ETHER>;
			power-domains = <&cpg_clocks>;
			phy-mode = "rmii";
			#address-cells = <1>;
			#size-cells = <0>;
			status = "disabled";
		};

		gic: interrupt-controller@f1001000 {
			compatible = "arm,gic-400";
			#interrupt-cells = <3>;
			#address-cells = <0>;
			interrupt-controller;
			reg = <0 0xf1001000 0 0x1000>, <0 0xf1002000 0 0x2000>,
			      <0 0xf1004000 0 0x2000>, <0 0xf1006000 0 0x2000>;
			interrupts = <GIC_PPI 9 (GIC_CPU_MASK_SIMPLE(8) | IRQ_TYPE_LEVEL_HIGH)>;
			clocks = <&mstp4_clks R8A7742_CLK_INTC_SYS>;
			clock-names = "clk";
			power-domains = <&cpg_clocks>;
		};

		cmt0: timer@ffca0000 {
			compatible = "renesas,cmt-48-r8a7742",
				     "renesas,cmt-48-gen2";
			reg = <0 0xffca0000 0 0x1004>;
			interrupts = <GIC_SPI 142 IRQ_TYPE_LEVEL_HIGH>,
				     <GIC_SPI 143 IRQ_TYPE_LEVEL_HIGH>;
			clocks = <&mstp1_clks R8A7742_CLK_CMT0>;
			clock-names = "fck";
			power-domains = <&cpg_clocks>;

			renesas,channels-mask = <0x60>;

			status = "disabled";
		};

		cmt1: timer@e6130000 {
			compatible = "renesas,cmt-48-r8a7742",
				     "renesas,cmt-48-gen2";
			reg = <0 0xe6130000 0 0x1004>;
			interrupts = <GIC_SPI 120 IRQ_TYPE_LEVEL_HIGH>,
				     <GIC_SPI 121 IRQ_TYPE_LEVEL_HIGH>,
				     <GIC_SPI 122 IRQ_TYPE_LEVEL_HIGH>,
				     <GIC_SPI 123 IRQ_TYPE_LEVEL_HIGH>,
				     <GIC_SPI 124 IRQ_TYPE_LEVEL_HIGH>,
				     <GIC_SPI 125 IRQ_TYPE_LEVEL_HIGH>,
				     <GIC_SPI 126 IRQ_TYPE_LEVEL_HIGH>,
				     <GIC_SPI 127 IRQ_TYPE_LEVEL_HIGH>;
			clocks = <&mstp3_clks R8A7742_CLK_CMT1>;
			clock-names = "fck";
			power-domains = <&cpg_clocks>;

			renesas,channels-mask = <0xff>;

			status = "disabled";
		};
	};

	thermal-zones {
		cpu_thermal: cpu-thermal {
			polling-delay-passive = <0>;
			polling-delay = <0>;

			thermal-sensors = <&thermal>;

			trips {
				cpu-crit {
					temperature = <95000>;
					hysteresis = <0>;
					type = "critical";
				};
			};
			cooling-maps {
			};
		};
	};

	timer {
		compatible = "arm,armv7-timer";
		interrupts-extended = <&gic GIC_PPI 13 (GIC_CPU_MASK_SIMPLE(8) | IRQ_TYPE_LEVEL_LOW)>,
				      <&gic GIC_PPI 14 (GIC_CPU_MASK_SIMPLE(8) | IRQ_TYPE_LEVEL_LOW)>,
				      <&gic GIC_PPI 11 (GIC_CPU_MASK_SIMPLE(8) | IRQ_TYPE_LEVEL_LOW)>,
				      <&gic GIC_PPI 10 (GIC_CPU_MASK_SIMPLE(8) | IRQ_TYPE_LEVEL_LOW)>;
	};

	/* External USB clock - can be overridden by the board */
	usb_extal_clk: usb_extal {
		compatible = "fixed-clock";
		#clock-cells = <0>;
		clock-frequency = <48000000>;
	};
};
